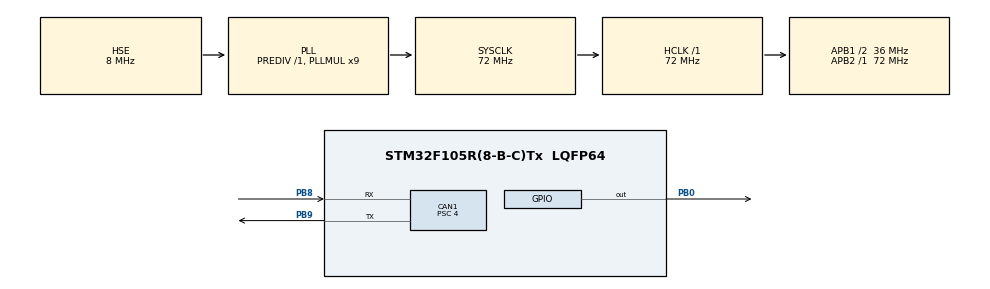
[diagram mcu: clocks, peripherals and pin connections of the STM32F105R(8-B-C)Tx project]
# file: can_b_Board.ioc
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CAN1.BS1=CAN_BS1_7TQ
CAN1.CalculateTimeBit=1000
CAN1.CalculateTimeQuantum=111.11111111111111
CAN1.Prescaler=4
CAN1.SJW=CAN_SJW_1TQ
Mcu.Family=STM32F1
Mcu.Name=STM32F105R(8-B-C)Tx
Mcu.Package=LQFP64
NVIC.CAN1_RX0_IRQn=true\:0\:0\:false\:false\:true\:true\:true
NVIC.PriorityGroup=NVIC_PRIORITYGROUP_4
PA13.Mode=Serial_Wire
PA13.Signal=SYS_JTMS-SWDIO
PA14.Mode=Serial_Wire
PA14.Signal=SYS_JTCK-SWCLK
PB0.Signal=GPIO_Output
PB8.Mode=Master
PB8.Signal=CAN1_RX
PB9.Mode=Master
PB9.Signal=CAN1_TX
PC14-OSC32_IN.Mode=LSE-External-Oscillator
PC14-OSC32_IN.Signal=RCC_OSC32_IN
PC15-OSC32_OUT.Mode=LSE-External-Oscillator
PC15-OSC32_OUT.Signal=RCC_OSC32_OUT
PD0-OSC_IN.Mode=HSE-External-Oscillator
PD0-OSC_IN.Signal=RCC_OSC_IN
PD1-OSC_OUT.Mode=HSE-External-Oscillator
PD1-OSC_OUT.Signal=RCC_OSC_OUT
ProjectManager.HeapSize=0x200
ProjectManager.StackSize=0x400
ProjectManager.TargetToolchain=MDK-ARM V5
RCC.AHBFreq_Value=72000000
RCC.APB1CLKDivider=RCC_HCLK_DIV2
RCC.APB1Freq_Value=36000000
RCC.APB1TimFreq_Value=72000000
RCC.APB2Freq_Value=72000000
RCC.APB2TimFreq_Value=72000000
RCC.HCLKFreq_Value=72000000
RCC.PLLMUL=RCC_PLL_MUL9
RCC.PLLSourceVirtual=RCC_PLLSOURCE_HSE
RCC.SYSCLKFreq_VALUE=72000000
RCC.SYSCLKSource=RCC_SYSCLKSOURCE_PLLCLK
RCC.USBFreq_Value=48000000
board=custom

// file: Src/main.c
/* USER CODE BEGIN Header */
/**
  ******************************************************************************
  * @file           : main.c
  * @brief          : Main program body
  ******************************************************************************
  * @attention
  *
  * <h2><center>&copy; Copyright (c) 2021 STMicroelectronics.
  * All rights reserved.</center></h2>
  *
  * This software component is licensed by ST under BSD 3-Clause license,
  * the "License"; You may not use this file except in compliance with the
  * License. You may obtain a copy of the License at:
  *                        opensource.org/licenses/BSD-3-Clause
  *
  ******************************************************************************
  */
/* USER CODE END Header */

#include "main.h"

/* USER CODE BEGIN PD */
#define MAX_CURRENT 10000
#define MIN_CURRENT -30000
/* USER CODE END PD */

CAN_HandleTypeDef hcan1;

/* USER CODE BEGIN PV */
CAN_TxHeaderTypeDef CAN1_TX;
CAN_RxHeaderTypeDef CAN1_RX;
uint16_t motor_data;
uint8_t TX_datas[8]= {0};
uint32_t mailbox;
HAL_StatusTypeDef can1_tx_status = HAL_ERROR;
uint32_t errors;
int cnt = 0;
/* USER CODE END PV */

void SystemClock_Config(void);
static void MX_GPIO_Init(void);
static void MX_CAN1_Init(void);
/* USER CODE BEGIN PFP */
void CANFILTER1_INIT(void);
/* USER CODE END PFP */

/* USER CODE BEGIN 0 */

void CANFILTER1_INIT(void){

  CAN_FilterTypeDef  CAN_FILTER1;

  CAN_FILTER1.FilterBank= 0;							//过滤器0
	CAN_FILTER1.FilterMode= CAN_FILTERMODE_IDMASK;
	CAN_FILTER1.FilterScale= CAN_FILTERSCALE_32BIT;		//32位
	CAN_FILTER1.FilterIdHigh= 0x0000;					//32位ID
	CAN_FILTER1.FilterIdLow= 0x0000;
	CAN_FILTER1.FilterMaskIdHigh= 0x0000;				//32位MASK
	CAN_FILTER1.FilterMaskIdLow= 0x0000;
	CAN_FILTER1.FilterFIFOAssignment= CAN_FILTER_FIFO0;	//过滤器0关联到FIFO0
	CAN_FILTER1.FilterActivation= ENABLE;				//激活过滤器0

	HAL_CAN_ConfigFilter( &hcan1,  &CAN_FILTER1);	//滤波器初始化

}

/* USER CODE END 0 */

int main(void)
{

  /* MCU Configuration--------------------------------------------------------*/

  /* Reset of all peripherals, Initializes the Flash interface and the Systick. */
  HAL_Init();

  /* Configure the system clock */
  SystemClock_Config();

  /* Initialize all configured peripherals */
  MX_GPIO_Init();
 	MX_CAN1_Init();
  /* USER CODE BEGIN 2 */

	HAL_CAN_Start(&hcan1);
  CANFILTER1_INIT();

	CAN1_TX.DLC = 0X08;
	CAN1_TX.ExtId = 0;
	CAN1_TX.IDE = CAN_ID_STD;
	CAN1_TX.RTR = CAN_RTR_DATA;
	CAN1_TX.StdId = 0X200;
	CAN1_TX.TransmitGlobalTime = DISABLE;
	motor_data = MAX_CURRENT*0.3;
	TX_datas[0] = motor_data>>8;
	TX_datas[1] = motor_data;
  can1_tx_status =  HAL_CAN_AddTxMessage(&hcan1,&CAN1_TX,TX_datas, &mailbox);
  /* USER CODE END 2 */

  /* Infinite loop */
  /* USER CODE BEGIN WHILE */
  while (1)
  {

//		HAL_GPIO_WritePin(GPIOB,GPIO_PIN_0,GPIO_PIN_RESET);
//		HAL_Delay(500);
//		HAL_GPIO_WritePin(GPIOB,GPIO_PIN_0,GPIO_PIN_SET);
//		HAL_Delay(500);
		HAL_CAN_AddTxMessage(&hcan1,&CAN1_TX,TX_datas, &mailbox);
		HAL_Delay(10);
		errors=HAL_CAN_GetError(&hcan1);
		cnt++;
    /* USER CODE END WHILE */

  }
}

void SystemClock_Config(void)
{
  RCC_OscInitTypeDef RCC_OscInitStruct = {0};
  RCC_ClkInitTypeDef RCC_ClkInitStruct = {0};

  /** Initializes the CPU, AHB and APB busses clocks
  */
  RCC_OscInitStruct.OscillatorType = RCC_OSCILLATORTYPE_HSE;
  RCC_OscInitStruct.HSEState = RCC_HSE_ON;
  RCC_OscInitStruct.HSEPredivValue = RCC_HSE_PREDIV_DIV1;
  RCC_OscInitStruct.HSIState = RCC_HSI_ON;
  RCC_OscInitStruct.Prediv1Source = RCC_PREDIV1_SOURCE_HSE;
  RCC_OscInitStruct.PLL.PLLState = RCC_PLL_ON;
  RCC_OscInitStruct.PLL.PLLSource = RCC_PLLSOURCE_HSE;
  RCC_OscInitStruct.PLL.PLLMUL = RCC_PLL_MUL9;
  RCC_OscInitStruct.PLL2.PLL2State = RCC_PLL_NONE;
  if (HAL_RCC_OscConfig(&RCC_OscInitStruct) != HAL_OK)
  {
    Error_Handler();
  }
  /** Initializes the CPU, AHB and APB busses clocks
  */
  RCC_ClkInitStruct.ClockType = RCC_CLOCKTYPE_HCLK|RCC_CLOCKTYPE_SYSCLK
                              |RCC_CLOCKTYPE_PCLK1|RCC_CLOCKTYPE_PCLK2;
  RCC_ClkInitStruct.SYSCLKSource = RCC_SYSCLKSOURCE_PLLCLK;
  RCC_ClkInitStruct.AHBCLKDivider = RCC_SYSCLK_DIV1;
  RCC_ClkInitStruct.APB1CLKDivider = RCC_HCLK_DIV2;
  RCC_ClkInitStruct.APB2CLKDivider = RCC_HCLK_DIV1;

  if (HAL_RCC_ClockConfig(&RCC_ClkInitStruct, FLASH_LATENCY_2) != HAL_OK)
  {
    Error_Handler();
  }
  /** Configure the Systick interrupt time
  */
  __HAL_RCC_PLLI2S_ENABLE();
}

static void MX_CAN1_Init(void)
{

  hcan1.Instance = CAN1;
  hcan1.Init.Prescaler = 4;
  hcan1.Init.Mode = CAN_MODE_NORMAL;
  hcan1.Init.SyncJumpWidth = CAN_SJW_1TQ;
  hcan1.Init.TimeSeg1 = CAN_BS1_7TQ;
  hcan1.Init.TimeSeg2 = CAN_BS2_1TQ;
  hcan1.Init.TimeTriggeredMode = DISABLE;
  hcan1.Init.AutoBusOff = DISABLE;
  hcan1.Init.AutoWakeUp = DISABLE;
  hcan1.Init.AutoRetransmission = DISABLE;
  hcan1.Init.ReceiveFifoLocked = DISABLE;
  hcan1.Init.TransmitFifoPriority = DISABLE;

  if (HAL_CAN_Init(&hcan1) != HAL_OK)
  {
    Error_Handler();
  }

}

static void MX_GPIO_Init(void)
{
  GPIO_InitTypeDef GPIO_InitStruct = {0};

  /* GPIO Ports Clock Enable */
  __HAL_RCC_GPIOC_CLK_ENABLE();
  __HAL_RCC_GPIOD_CLK_ENABLE();
  __HAL_RCC_GPIOB_CLK_ENABLE();
  __HAL_RCC_GPIOA_CLK_ENABLE();

  /*Configure GPIO pin Output Level */
  HAL_GPIO_WritePin(GPIOB, GPIO_PIN_0, GPIO_PIN_RESET);

  /*Configure GPIO pin : PB0 */
  GPIO_InitStruct.Pin = GPIO_PIN_0;
  GPIO_InitStruct.Mode = GPIO_MODE_OUTPUT_PP;
  GPIO_InitStruct.Pull = GPIO_NOPULL;
  GPIO_InitStruct.Speed = GPIO_SPEED_FREQ_LOW;
  HAL_GPIO_Init(GPIOB, &GPIO_InitStruct);

}

void Error_Handler(void)
{
}

/************************ (C) COPYRIGHT STMicroelectronics *****END OF FILE****/
